AUTOSAR XML (schema 4-0-3)
standard types defined: boolean, float32, float64, sint16, sint32, sint8, uint16, uint32, uint8
package /BSWScheduler/BswImplementations
  bsw implementation BswImplementation: programming-language=C, sw-version=1.0.0, vendor-id=20, ar-release-version=1.0.0, behavior=WdgM/InternalBehavior, vendor-api-infix=abc
    code-descriptors:
      code Code: artifact-descriptors=autosar-engineering-object={short-label=Label, category=Category}
    resource consumption ResourceConsumption
package /BSWScheduler/BswModuleDescriptions
  bsw module description Wdg: module-id=102
    bsw internal behavior InternalBehavior
      exclusive area Reentrant
      4 x bsw schedulable entity, all with can-enter-exclusive-area=InternalBehavior/Reentrant:
        Wdg_Init: implemented-entry=WdgIf_Init
        Wdg_SetMode: implemented-entry=WdgIf_SetMode
        Wdg_SetTriggerCondition: implemented-entry=WdgIf_SetTriggerCondition
        Wdg_GetVersionInfo: implemented-entry=WdgIf_GetVersionInfo
  bsw module description WdgIf: module-id=43
    bsw internal behavior InternalBehavior
      exclusive area Reentrant
      bsw schedulable entity SetMode: can-enter-exclusive-area=InternalBehavior/Reentrant, implemented-entry=Wdg_SetMode
      bsw schedulable entity WdgIf_SetTriggerCondition: can-enter-exclusive-area=InternalBehavior/Reentrant, implemented-entry=Wdg_GetTriggerCondition
      bsw schedulable entity WdgIf_GetVersionInfo: can-enter-exclusive-area=InternalBehavior/Reentrant, implemented-entry=Wdg_GetVersionInfo
  bsw module description WdgM: module-id=13, provided-entrys=MainFunction
    bsw internal behavior InternalBehavior
      4 x exclusive area:
        Reentrant
        CriticalSection_FirstExpiredSEID
        CriticalSection_Supervision
        CriticalSection_SetTriggerCondition
      bsw schedulable entity MainFunction: can-enter-exclusive-area=[InternalBehavior/Reentrant, CriticalSection_FirstExpiredSEID, CriticalSection_Supervision, CriticalSection_SetTriggerCondition], implemented-entry=MainFunction
      bsw timing event TimingEvent_MainFunction: starts-on-event=MainFunction, period=0.1
package /BSWScheduler/BswModuleEntrys
  10 x bsw module entry, all with is-synchronous=true, sw-service-impl-policy=STANDARD:
    BswModuleEntryDummy_Wdg: service-id=254, is-reentrant=true, call-type=SCHEDULED, execution-context=TASK
    BswModuleEntryDummy_WdgIf: service-id=254, is-reentrant=true, call-type=SCHEDULED, execution-context=TASK
    MainFunction: service-id=8, is-reentrant=false, call-type=SCHEDULED, execution-context=TASK
    WdgIf_GetVersionInfo: service-id=4, is-reentrant=false, call-type=CALLBACK, execution-context=UNSPECIFIED
    WdgIf_Init: service-id=0, is-reentrant=false, call-type=REGULAR, execution-context=UNSPECIFIED
    WdgIf_SetMode: service-id=1, is-reentrant=false, call-type=CALLBACK, execution-context=UNSPECIFIED
    WdgIf_SetTriggerCondition: service-id=3, is-reentrant=false, call-type=CALLBACK, execution-context=UNSPECIFIED
    Wdg_GetTriggerCondition: service-id=2, is-reentrant=false, call-type=CALLBACK, execution-context=UNSPECIFIED
    Wdg_GetVersionInfo: service-id=3, is-reentrant=true, call-type=REGULAR, execution-context=UNSPECIFIED
    Wdg_SetMode: service-id=1, is-reentrant=true, call-type=CALLBACK, execution-context=TASK
package /ImplDataTypes
  5 x impl type, all with category=VALUE:
    ActionRequest: base-type=boolean
    ButtonState: base-type=boolean
    LedState: base-type=boolean
    LockState: base-type=boolean
    Rte_ModeType_WdgM_Mode: base-type=uint8
  mode declaration group WdgMMode: category=ALPHABETIC_ORDER, initial-mode=SUPERVISION_OK
    5 x mode:
      SUPERVISION_OK
      SUPERVISION_FAILED
      SUPERVISION_EXPIRED
      SUPERVISION_STOPPED
      SUPERVISION_DEACTIVATED
  impl type WdgM_CheckpointIdType: category=VALUE, base-type=uint16
  impl type WdgM_SupervisedEntityIdType: category=VALUE, base-type=uint16
  impl type WindowPosition: category=VALUE, base-type=uint8
package /Interfaces
  sender receiver interface IfActionRequest
    data up: type=ActionRequest
    data down: type=ActionRequest
  5 x client server interface:
    IfButtonState
      operation GetButtonState
        arg up: type=ButtonState, direction=OUT
        arg down: type=ButtonState, direction=OUT
    IfLedState
      operation SetLedState
        arg state: type=LedState, direction=IN
      operation SetLedState2
        arg state: type=LedState, direction=IN
      operation SetLedState3
        arg state: type=LedState, direction=IN
    IfLockState
      operation GetLockState
        arg state: type=LockState, direction=OUT
      operation GetLockState2
        arg state: type=LockState, direction=OUT
      operation GetLockState3
        arg state: type=LockState, direction=OUT
    IfWindowPosition
      operation SetWindowPosition
        arg position: type=WindowPosition, direction=IN
    WdgM_AliveSupervision: is-service=true, service-kind=WATCH-DOG-MANAGER
      operation CheckpointReached: possible-error=E_NOT_OK
        arg checkpointId: type=WdgM_CheckpointIdType, direction=IN
      error E_NOT_OK: error-code=1
  mode switch interface WdgM_GlobalMode: is-service=true, service-kind=WATCH-DOG-MANAGER
    mode group currentMode: type=WdgMMode
  mode switch interface WdgM_IndividualMode: is-service=true, service-kind=WATCH-DOG-MANAGER
    mode group currentMode: type=WdgMMode
package /PowerWindowController
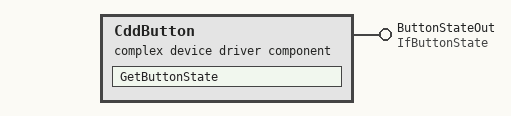
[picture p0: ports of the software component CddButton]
  complex device driver sw component type CddButton
    provide port ButtonStateOut: provided-interface=IfButtonState
    behavior IB_CB: handle-termination-and-restart=NO-SUPPORT
      operation invoked event OperationInvokedEvent: start-on-event=GetButtonState, operation=ButtonStateOut.GetButtonState
      runnable GetButtonState
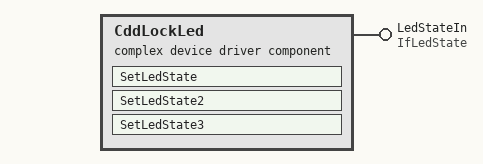
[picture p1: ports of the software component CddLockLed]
  complex device driver sw component type CddLockLed
    provide port LedStateIn: provided-interface=IfLedState
      provided-com-specs:
        operation=SetLedState, queue-length=0
        operation=SetLedState2, queue-length=0
        operation=SetLedState3, queue-length=0
    behavior IB_CLL: handle-termination-and-restart=NO-SUPPORT
      operation invoked event OperationInvokedEvent: start-on-event=SetLedState, operation=LedStateIn.SetLedState
      operation invoked event OperationInvokedEvent2: start-on-event=SetLedState2, operation=LedStateIn.SetLedState2
      operation invoked event OperationInvokedEvent3: start-on-event=SetLedState3, operation=LedStateIn.SetLedState3
      runnable SetLedState: runnable-entity-argument=symbol=state
      runnable SetLedState2: runnable-entity-argument=symbol=state
      runnable SetLedState3: runnable-entity-argument=symbol=state
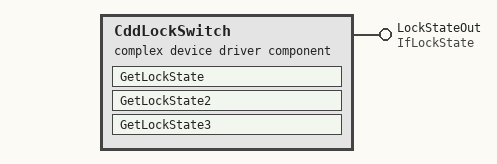
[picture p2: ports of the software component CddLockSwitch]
  complex device driver sw component type CddLockSwitch
    provide port LockStateOut: provided-interface=IfLockState
      provided-com-specs:
        operation=GetLockState, queue-length=1
        operation=GetLockState2, queue-length=1
        operation=GetLockState3, queue-length=1
    behavior IB_CLS: handle-termination-and-restart=NO-SUPPORT
      operation invoked event OperationInvokedEvent: start-on-event=GetLockState, operation=LockStateOut.GetLockState
      operation invoked event OperationInvokedEvent2: start-on-event=GetLockState2, operation=LockStateOut.GetLockState2
      operation invoked event OperationInvokedEvent3: start-on-event=GetLockState3, operation=LockStateOut.GetLockState3
      runnable GetLockState: runnable-entity-argument=symbol=state
      runnable GetLockState2: runnable-entity-argument=symbol=state
      runnable GetLockState3: runnable-entity-argument=symbol=state
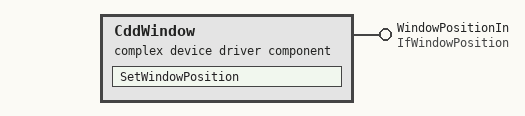
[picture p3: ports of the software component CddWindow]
  complex device driver sw component type CddWindow
    provide port WindowPositionIn: provided-interface=IfWindowPosition
    behavior IB_CW: handle-termination-and-restart=NO-SUPPORT
      operation invoked event OperationInvokedEvent: start-on-event=SetWindowPosition, operation=WindowPositionIn.SetWindowPosition
      runnable SetWindowPosition
  composition sw component type PWCTopLevel
    7 x component:
      CddButton: type=CddButton
      CddWindow: type=CddWindow
      PowerWindowController: type=PowerWindowController
      SensorButton: type=SensorButton
      CddLockLed: type=CddLockLed
      CddLockSwitch: type=CddLockSwitch
      WdgM: type=WdgM
    connect CddButton.ButtonStateOut -> SensorButton.ButtonStateIn
    connect SensorButton.ActionRequestOut -> PowerWindowController.ActionRequestIn
    connect CddWindow.WindowPositionIn -> PowerWindowController.WindowPositionOut
    connect CddLockLed.LedStateIn -> SensorButton.LedStateOut
    connect CddLockSwitch.LockStateOut -> SensorButton.LockStateIn
    connect WdgM.alive001 -> SensorButton.se1
    connect WdgM.alive002 -> SensorButton.se2
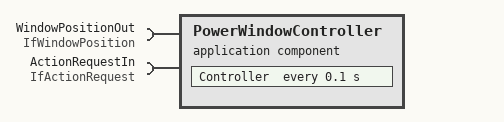
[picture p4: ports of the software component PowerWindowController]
  application sw component type PowerWindowController
    require port WindowPositionOut: required-interface=IfWindowPosition
    require port ActionRequestIn: required-interface=IfActionRequest
    behavior IB_PWC: handle-termination-and-restart=NO-SUPPORT
      timing event TimingEvent: start-on-event=Controller, period=0.1
      runnable Controller
        data-receive-point-by-arguments:
          access VariableAccess: accessed-variable=ActionRequestIn.up
          access VariableAccess1: accessed-variable=ActionRequestIn.down
        sync call SynchronousServerCallPoint: operation=WindowPositionOut.SetWindowPosition, timeout=0
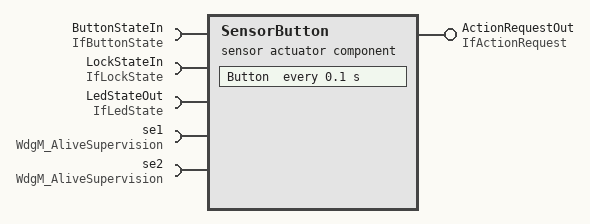
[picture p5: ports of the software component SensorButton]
  sensor actuator sw component type SensorButton: sensor-actuator=CddButton
    provide port ActionRequestOut: provided-interface=IfActionRequest
      provided-com-specs:
        data-element=down, transmission-acknowledge=timeout=0, init-value=TextValue:FALSE
        data-element=up, transmission-acknowledge=timeout=0, init-value=TextValue:FALSE
    5 x require port:
      ButtonStateIn: required-interface=IfButtonState
      LockStateIn: required-com-specs=[GetLockState, GetLockState2, GetLockState3], required-interface=IfLockState
      LedStateOut: required-com-specs=[SetLedState, SetLedState2, SetLedState3], required-interface=IfLedState
      se1: required-interface=WdgM_AliveSupervision
      se2: required-interface=WdgM_AliveSupervision
    behavior IB_SB: handle-termination-and-restart=NO-SUPPORT
      timing event TimingEvent: start-on-event=Button, period=0.1
      runnable Button
        data-send-points:
          access VariableAccess: accessed-variable=ActionRequestOut.up
          access VariableAccess1: accessed-variable=ActionRequestOut.down
        9 x sync call, all with timeout=0:
          SSCP_ButtonStateIn_GetButtonState: operation=ButtonStateIn.GetButtonState
          SSCP_LockStateIn_GetLockState: operation=LockStateIn.GetLockState
          SSCP_LedStateOut_SetLedState: operation=LedStateOut.SetLedState
          SSCP_se1_CheckpointReached: operation=se1.CheckpointReached
          SSCP_LedStateOut_SetLedState2: operation=LedStateOut.SetLedState2
          SSCP_LedStateOut_SetLedState3: operation=LedStateOut.SetLedState3
          SSCP_LockStateIn_GetLockState2: operation=LockStateIn.GetLockState2
          SSCP_LockStateIn_GetLockState3: operation=LockStateIn.GetLockState3
          SSCP_se4_CheckpointReached: operation=se2.CheckpointReached
package /Services
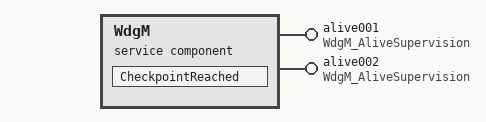
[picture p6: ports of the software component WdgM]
  service sw component type WdgM
    provide port alive001: server-com-spec{operation=CheckpointReached, queue-length=1}, provided-interface=WdgM_AliveSupervision
    provide port alive002: provided-interface=WdgM_AliveSupervision
    behavior InternalBehavior: handle-termination-and-restart=NO-SUPPORT, supports-multiple-instantiation=true
      operation invoked event OperationInvokedEvent_alive001: start-on-event=CheckpointReached, operation=alive001.CheckpointReached
      operation invoked event OperationInvokedEvent_alive002: start-on-event=CheckpointReached, operation=alive002.CheckpointReached
      port-api-options:
        {enable-take-address=false, indirect-api=false, port-defined-argument-value{value=constant-reference={short-label=ReferenceToConstant, constant=WdgMSupervisedEntity_0}, value-type=WdgM_SupervisedEntityIdType}, port=alive001}
        {enable-take-address=false, indirect-api=false, port-defined-argument-value{value=constant-reference={short-label=ReferenceToConstant, constant=WdgMSupervisedEntity_1}, value-type=WdgM_SupervisedEntityIdType}, port=alive002}
      runnable CheckpointReached: can-be-invoked-concurrently=true, symbol=WdgM_CheckpointReached
  constant specification WdgMSupervisedEntity_0: value-spec=Value:0
  constant specification WdgMSupervisedEntity_1: value-spec=Value:1
package /System
  ecuc value collection EcucValueCollection: ecu-extract=SystemPWC, ecuc-values=[Os, Rte]
  system SystemPWC: system-version=1.0.0
    root-software-compositions:
      root sw composition prototype RootSwCompositionPrototype: software-composition=PWCTopLevel
